# ESP32S31_RADIO register map
Vendor: Espressif; Series: ESP32-S31; File version: 3.52
Registers are 32-bit, read-write, no defined reset value unless marked. A register's access mark holds for its fields unless they carry their own. Offsets are from the block's base; [hi:lo] are bit positions.

## PHY_AGC_ORACLE — OPAQUE PHY AGC, PBus-pulse, antenna, RX-compensation, DC-memory, post-initialization and 11b-control registers recovered from complete, finite rev0 ROM/blob bodies. One physical register has one identity even when independent bodies prove different fields. Names describe their proven operation role, not an unevidenced electrical identity.
Base 0x20100000
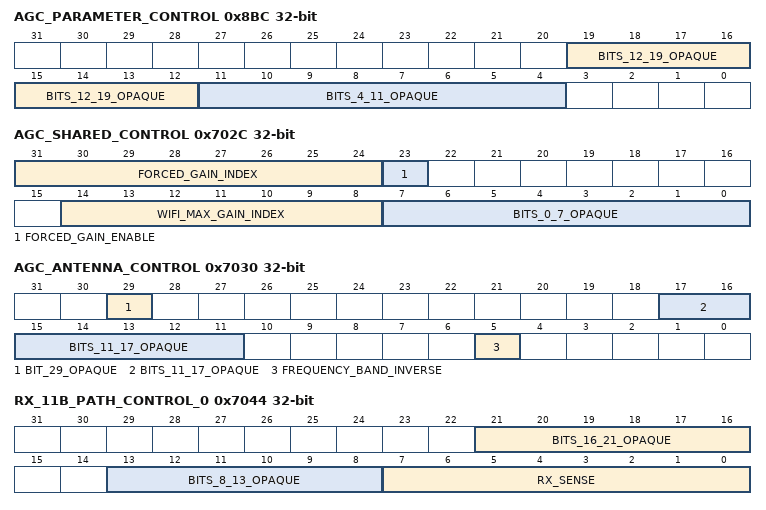
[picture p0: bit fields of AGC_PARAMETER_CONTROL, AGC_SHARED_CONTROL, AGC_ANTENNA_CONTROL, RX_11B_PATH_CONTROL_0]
0x8BC AGC_PARAMETER_CONTROL — Project-assigned name. Complete phy_agc_reg_init performs two fresh-read parameter-derived field replacements.
  [19:12] BITS_12_19_OPAQUE — Opaque: meaning not established. Second update writes the low eight bits of parameter byte 0x120 plus 0x50 into bits 19:12.
  [11:4] BITS_4_11_OPAQUE — Opaque: meaning not established. First update writes parameter byte 0x121 into bits 11:4.
0x702C AGC_SHARED_CONTROL — Project-assigned name. Shared word updated by complete phy_agc_reg_init, phy_enable_agc, phy_pbus_force_mode, phy_force_rx_gain, phy_set_rx_comp_new, and the final limit tail of phy_set_rx_gain_table.
  [31:24] FORCED_GAIN_INDEX — Project-assigned name. Receive-gain table index applied while FORCED_GAIN_ENABLE is set. Complete phy_force_rx_gain and the Wi-Fi path of librftest force_rx_gain write their gain argument here before the enable bit; complete phy_agc_reg_init and the delayed phy_pbus_force_mode tail write 0x32 into bits 31:24 before pulsing bit 23, so a PBus work-mode transition replaces any previously forced index.
  [23] FORCED_GAIN_ENABLE — Project-assigned name. Enables the forced receive-gain index in FORCED_GAIN_INDEX. Complete phy_force_rx_gain and the Wi-Fi path of librftest force_rx_gain replace it with the low bit of their enable argument; librftest clears it and waits 5 us after writing the index before setting it. Complete phy_enable_agc and the delayed tail of phy_pbus_force_mode pulse it.
  [14:8] WIFI_MAX_GAIN_INDEX — Project-assigned name. Highest Wi-Fi receive-gain table index: librftest rx_max_gain returns these bits for its Wi-Fi path. Complete phy_agc_reg_init writes parameter byte 0x121 and phy_set_rx_gain_table the final Wi-Fi RX gain index after table publication.
  [7:0] BITS_0_7_OPAQUE — Opaque: meaning not established. Complete phy_set_rx_comp_new writes 0xed into bits 7:0.
0x7030 AGC_ANTENNA_CONTROL — Project-assigned name. Shared word updated independently by complete AGC enable/disable, antenna initialization and frequency-band selection bodies.
  [29] BIT_29_OPAQUE — Opaque: meaning not established. Instruction-exact AGC disable/enable gate.
  [17:11] BITS_11_17_OPAQUE — Opaque: meaning not established. Complete phy_ant_init writes 0x34 into bits 17:11.
  [5] FREQUENCY_BAND_INVERSE — Project-assigned name. Complete phy_freq_band_reg_set writes the inverse of the caller low bit.
0x703C DC_MEMORY_CONTROL — Project-assigned name. Complete phy_dc_mem_clr sets then clears bit 20 using a fresh read before each write.
  [20] BIT_20_OPAQUE — Opaque: meaning not established. Instruction-exact set/clear pulse; the vendor symbol qualifies the operation while the electrical effect remains unknown.
0x7044 RX_11B_PATH_CONTROL_0 — Project-assigned name. Complete phy_bb_agc_reg_update writes the full word; complete phy_rx_11b_opt later replaces two six-bit fields and complete phy_rx_sense_set the low byte.
  [21:16] BITS_16_21_OPAQUE — Opaque: meaning not established. Complete phy_rx_11b_opt replaces bits 21:16.
  [13:8] BITS_8_13_OPAQUE — Opaque: meaning not established. Complete phy_rx_11b_opt replaces bits 13:8.
  [7:0] RX_SENSE — Project-assigned name. Receive-sensitivity setting complete phy_rx_sense_set publishes.
0x7048 WORD_7048_OPAQUE wo — Opaque: meaning not established. Complete phy_bb_agc_reg_update writes 0xff7da4f3.
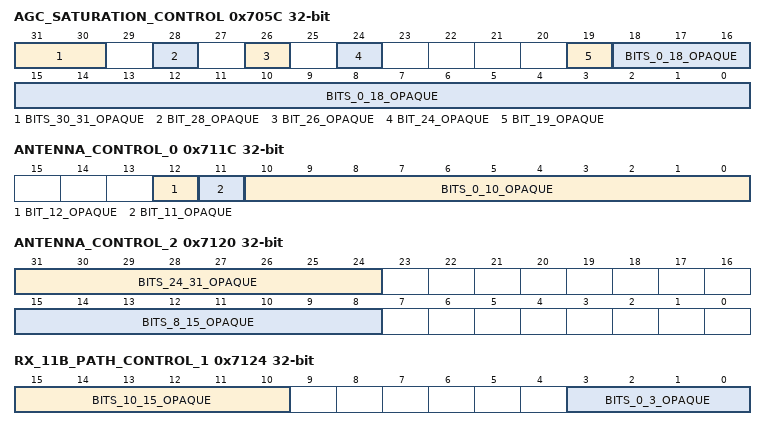
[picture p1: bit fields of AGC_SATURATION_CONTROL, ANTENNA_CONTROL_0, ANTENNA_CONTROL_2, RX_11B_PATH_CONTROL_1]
0x705C AGC_SATURATION_CONTROL — Project-assigned name. Shared word updated by complete phy_agc_reg_init, both phy_rfrx_sat_rst branches, and phy_reg_update_new.
  [31:30] BITS_30_31_OPAQUE — Opaque: meaning not established. Bits 31:30 are the adjacent high pair in the discontiguous 0xd1080000 mask set or cleared by phy_rfrx_sat_rst.
  [28] BIT_28_OPAQUE — Opaque: meaning not established. One member of the discontiguous 0xd1080000 mask set or cleared by phy_rfrx_sat_rst.
  [26] BIT_26_OPAQUE — Opaque: meaning not established. Complete phy_reg_update_new sets bit 26.
  [24] BIT_24_OPAQUE — Opaque: meaning not established. One member of the discontiguous 0xd1080000 mask set or cleared by phy_rfrx_sat_rst.
  [19] BIT_19_OPAQUE — Opaque: meaning not established. One member of the discontiguous 0xd1080000 mask set or cleared by phy_rfrx_sat_rst.
  [18:0] BITS_0_18_OPAQUE — Opaque: meaning not established. Bits 18:0 receive 0xbb8 during AGC initialization and 0x400 or 0x800 in the two RF RX saturation phases.
0x7064 SATURATION_GAIN_LOW wo — Project-assigned name. Complete rev0 ROM phy_wifi_agc_sat_gain writes its argument here first.
  [31:0] VALUE — Project-assigned name.
0x7068 RF_RX_SATURATION_CONFIG wo — Project-assigned name. Complete phy_rfrx_sat_rst writes the full value 0x00000404 before either branch.
0x7094 AGC_GAIN_LIMIT_LOW — Project-assigned name. Holds the seven-bit AGC initial receive-gain index INITIAL_GAIN_INDEX, which complete phy_agc_reg_init derives from a parameter byte and librftest rx_init_gain sets with RX_GAIN_LIMIT_CONTROL.
  [8:2] INITIAL_GAIN_INDEX — Project-assigned name. AGC initial receive-gain index: librftest rx_init_gain writes its gain argument here and into RX_GAIN_LIMIT_CONTROL.INITIAL_GAIN_INDEX. Complete phy_agc_reg_init writes the low seven bits of parameter byte 0x121 minus one.
0x70A0 RX_COMPENSATION_HIGH_CONTROL — Project-assigned name. Complete phy_set_rx_comp_new performs its second fresh-read update here.
  [31:24] BITS_24_31_OPAQUE — Opaque: meaning not established. Complete phy_set_rx_comp_new writes 0xed into bits 31:24.
0x70A4 CSI_DUMP_FORCE_CONTROL — Project-assigned name. Complete phy_csidump_force_lltf_cfg replaces bit fifteen from the caller low bit.
  [15] FORCE_LLTF — Project-assigned name.
0x7104 RX_11B_WINDOW_CONTROL — Project-assigned name. Complete phy_bb_agc_reg_update writes the full word; phy_rx_11b_opt and phy_reg_update_new replace the same low nine-bit field with independently evidenced values.
  [8:0] BITS_0_8_OPAQUE — Opaque: meaning not established. Complete phy_rx_11b_opt writes 0x1c8 and complete phy_reg_update_new writes 0x1c0 into bits 8:0.
0x7114 SATURATION_GAIN_HIGH wo — Project-assigned name. Complete rev0 ROM phy_wifi_agc_sat_gain writes its argument here second.
  [31:0] VALUE — Project-assigned name.
0x711C ANTENNA_CONTROL_0 — Project-assigned name. First fresh-read update of complete phy_ant_init clears two independently evidenced field groups; complete phy_ant_dft_cfg replaces bit 11 with its caller low bit.
  [12] BIT_12_OPAQUE — Opaque: meaning not established. Complete phy_ant_init independently clears bit 12.
  [11] BIT_11_OPAQUE — Opaque: meaning not established. Complete phy_ant_dft_cfg writes zero to disable antenna diversity and one to enable it.
    0=DISABLED (Disable the recovered antenna-diversity path.); 1=ENABLED (Enable the recovered antenna-diversity path.)
  [10:0] BITS_0_10_OPAQUE — Opaque: meaning not established. Complete phy_ant_init clears bits 10:0.
0x7120 ANTENNA_CONTROL_2 — Project-assigned name. Third fresh-read update of complete phy_ant_init writes the same value into two separated bytes.
  [31:24] BITS_24_31_OPAQUE — Opaque: meaning not established. Complete phy_ant_init writes 0x1e into bits 31:24.
  [15:8] BITS_8_15_OPAQUE — Opaque: meaning not established. Complete phy_ant_init writes 0x1e into bits 15:8.
0x7124 RX_11B_PATH_CONTROL_1 — Project-assigned name. Complete phy_bb_agc_reg_update writes the full word; complete phy_rx_11b_opt later replaces two fields.
  [15:10] BITS_10_15_OPAQUE — Opaque: meaning not established. Complete phy_rx_11b_opt replaces bits 15:10.
  [3:0] BITS_0_3_OPAQUE — Opaque: meaning not established. Complete phy_rx_11b_opt replaces bits 3:0.
0x7128 AGC_INIT_HIGH_CONTROL — Project-assigned name. Canonical multifunction word. Complete phy_agc_reg_init replaces the high byte with 0xd2; complete hal_init_bf later performs one volatile full-word synchronization/status read whose value is unused.
  [31:24] BITS_24_31_OPAQUE — Opaque: meaning not established. Instruction-exact 0xd2 value in bits 31:24.
0x713C RX_GAIN_LIMIT_CONTROL — Project-assigned name. Holds the seven-bit AGC initial receive-gain index INITIAL_GAIN_INDEX, written by phy_agc_reg_init, the final phy_set_rx_gain_table tail and librftest rx_init_gain together with AGC_GAIN_LIMIT_LOW.
  [24:18] INITIAL_GAIN_INDEX — Project-assigned name. AGC initial receive-gain index: librftest rx_init_gain writes its gain argument here and into AGC_GAIN_LIMIT_LOW.INITIAL_GAIN_INDEX. Bits 24:18 receive parameter byte 0x121 minus one during initialization and the final Wi-Fi index capped at 0x4c after table publication.
0x78A4 WORD_78A4_OPAQUE wo — Opaque: meaning not established. Complete phy_bb_agc_reg_update writes 0x0001721f.
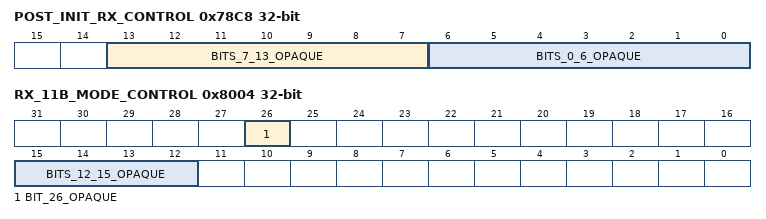
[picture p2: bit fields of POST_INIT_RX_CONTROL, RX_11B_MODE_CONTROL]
0x78C8 POST_INIT_RX_CONTROL — Project-assigned name. Complete phy_reg_update_new performs two fresh-read field replacements in this order.
  [13:7] BITS_7_13_OPAQUE — Opaque: meaning not established. Second fresh-read update replaces bits 13:7 with 0x17.
  [6:0] BITS_0_6_OPAQUE — Opaque: meaning not established. First fresh-read update replaces bits 6:0 with 0x17.
0x7D4C FTM_CONTROL — Project-assigned name. Complete phy_set_ftm_en replaces bit zero with its one-bit argument.
  [0] ENABLE — Project-assigned name. One-bit FTM enable argument.
0x8004 RX_11B_MODE_CONTROL — Project-assigned name. Complete phy_bb_agc_reg_update clears bit 26; complete phy_rx_11b_opt replaces bits 15:12.
  [26] BIT_26_OPAQUE — Opaque: meaning not established. Complete phy_bb_agc_reg_update clears bit 26.
  [15:12] BITS_12_15_OPAQUE — Opaque: meaning not established. Complete phy_rx_11b_opt replaces bits 15:12.
0x8010 WORD_8010_OPAQUE wo — Opaque: meaning not established. Complete phy_bb_agc_reg_update writes 0x000852a1.
0x8018 WORD_8018_OPAQUE wo — Opaque: meaning not established. Complete phy_bb_agc_reg_update writes 0x00600030.
0x801C WORD_801C_OPAQUE wo — Opaque: meaning not established. Complete phy_bb_agc_reg_update writes 0x010000a0.
0x8020 WORD_8020_OPAQUE wo — Opaque: meaning not established. Complete phy_bb_agc_reg_update writes 0x00000180.
0x8028 WORD_8028_OPAQUE wo — Opaque: meaning not established. Complete phy_bb_agc_reg_update writes 0xc0403020.
0x802C WORD_802C_OPAQUE wo — Opaque: meaning not established. Complete phy_bb_agc_reg_update writes 0x01000080.
0x8070 WORD_8070_OPAQUE wo — Opaque: meaning not established. Complete phy_bb_agc_reg_update writes 0x000008c7.
0x8078 AGC_UPDATE_8078_CONTROL — Project-assigned name. Complete phy_bb_agc_reg_update sets bits 22:20.
  [22:20] BITS_20_22_OPAQUE — Opaque: meaning not established. Complete phy_bb_agc_reg_update sets all three bits.
